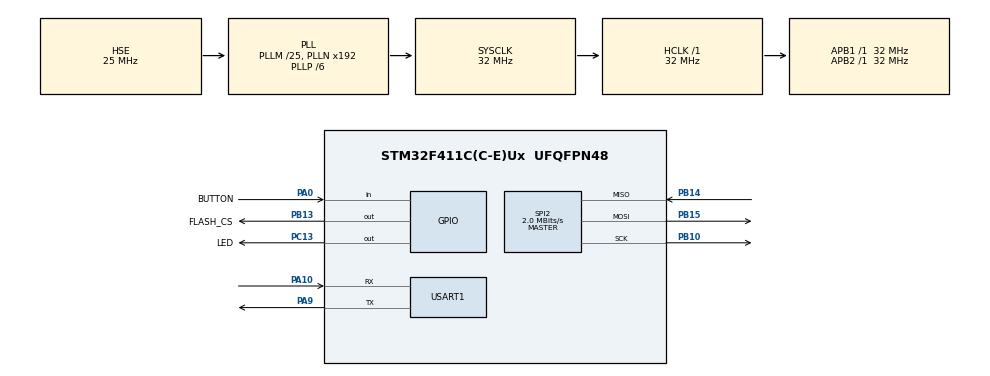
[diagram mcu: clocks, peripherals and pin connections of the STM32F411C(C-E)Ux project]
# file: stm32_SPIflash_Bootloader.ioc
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Mcu.Family=STM32F4
Mcu.Name=STM32F411C(C-E)Ux
Mcu.Package=UFQFPN48
NVIC.PriorityGroup=NVIC_PRIORITYGROUP_4
NVIC.USART1_IRQn=true\:0\:0\:false\:false\:true\:true\:true\:true
PA0-WKUP.GPIO_Label=BUTTON
PA0-WKUP.GPIO_PuPd=GPIO_PULLUP
PA0-WKUP.Signal=GPIO_Input
PA10.Mode=Asynchronous
PA10.Signal=USART1_RX
PA9.Mode=Asynchronous
PA9.Signal=USART1_TX
PB10.Mode=Full_Duplex_Master
PB10.Signal=SPI2_SCK
PB13.GPIO_Label=FLASH_CS
PB13.Signal=GPIO_Output
PB14.Mode=Full_Duplex_Master
PB14.Signal=SPI2_MISO
PB15.Mode=Full_Duplex_Master
PB15.Signal=SPI2_MOSI
PC13-ANTI_TAMP.GPIO_Label=LED
PC13-ANTI_TAMP.Signal=GPIO_Output
PH0\ -\ OSC_IN.Mode=HSE-External-Oscillator
PH0\ -\ OSC_IN.Signal=RCC_OSC_IN
PH1\ -\ OSC_OUT.Mode=HSE-External-Oscillator
PH1\ -\ OSC_OUT.Signal=RCC_OSC_OUT
ProjectManager.HeapSize=0x200
ProjectManager.StackSize=0x400
ProjectManager.TargetToolchain=STM32CubeIDE
RCC.48MHZClocksFreq_Value=48000000
RCC.AHBFreq_Value=32000000
RCC.APB1Freq_Value=32000000
RCC.APB1TimFreq_Value=32000000
RCC.APB2Freq_Value=32000000
RCC.APB2TimFreq_Value=32000000
RCC.CortexFreq_Value=32000000
RCC.HCLKFreq_Value=32000000
RCC.HSE_VALUE=25000000
RCC.HSI_VALUE=16000000
RCC.LSE_VALUE=32768
RCC.PLLM=25
RCC.PLLP=RCC_PLLP_DIV6
RCC.PLLSourceVirtual=RCC_PLLSOURCE_HSE
RCC.SYSCLKFreq_VALUE=32000000
RCC.SYSCLKSource=RCC_SYSCLKSOURCE_PLLCLK
RCC.VCOOutputFreq_Value=192000000
SPI2.BaudRatePrescaler=SPI_BAUDRATEPRESCALER_16
SPI2.CalculateBaudRate=2.0 MBits/s
SPI2.Direction=SPI_DIRECTION_2LINES
SPI2.Mode=SPI_MODE_MASTER
SPI2.VirtualType=VM_MASTER
USART1.VirtualMode=VM_ASYNC
board=custom

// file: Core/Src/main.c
/* USER CODE BEGIN Header */
/**
  ******************************************************************************
  * @file           : main.c
  * @brief          : Main program body
  ******************************************************************************
  * @attention
  *
  * Copyright (c) 2024 STMicroelectronics.
  * All rights reserved.
  *
  * This software is licensed under terms that can be found in the LICENSE file
  * in the root directory of this software component.
  * If no LICENSE file comes with this software, it is provided AS-IS.
  *
  ******************************************************************************
  */
/* USER CODE END Header */
#include "main.h"

/* USER CODE BEGIN Includes */
#include "stdio.h"
#include "boot.h"
#include "exflash.h"
/* USER CODE END Includes */

SPI_HandleTypeDef hspi2;

UART_HandleTypeDef huart1;
uint8_t rxdata[2];

void SystemClock_Config(void);
static void MX_GPIO_Init(void);
static void MX_USART1_UART_Init(void);
static void MX_SPI2_Init(void);
/* USER CODE BEGIN PFP */
extern void uart_int(uint8_t byte);
/* USER CODE END PFP */

/* USER CODE BEGIN 0 */
#define PUTCHAR_PROTOTYPE int __io_putchar(int ch)

PUTCHAR_PROTOTYPE
{
	//HAL_UART_Transmit(&huart1, &ch, 1, HAL_MAX_DELAY);
	//return ch;
}

uint8_t wbuff[16], rbuff[16];
void HAL_UART_RxCpltCallback(UART_HandleTypeDef *huart)
{
	if(huart == &huart1)
	{
		uart_int(rxdata[0]);
		HAL_UART_Receive_IT(&huart1, &rxdata[0], 1);
	}
}

/* USER CODE END 0 */

int main(void)
{

  /* MCU Configuration--------------------------------------------------------*/

  /* Reset of all peripherals, Initializes the Flash interface and the Systick. */
  HAL_Init();

  /* Configure the system clock */
  SystemClock_Config();

  /* Initialize all configured peripherals */
  MX_GPIO_Init();
  MX_USART1_UART_Init();
  MX_SPI2_Init();
  /* USER CODE BEGIN 2 */

  ef_readid();

  ef_GlobalBlockProtectionUnlock();
  HAL_UART_Receive_IT(&huart1, &rxdata[0], 1);

  ef_EraseSector(0x200000);

  for(int i=0;i <16;i++) wbuff[i] = i+20;

  ef_WriteBuffer(wbuff, 0x200000 , 16);

  HAL_Delay(100);

  ef_ReadBuffer(&rbuff[0], 0x200000 , 16);

  for(int i=0;i <16;i++)
  {
	  printf("%d ", rbuff[i]);
  }

  /* USER CODE END 2 */

  /* Infinite loop */
  /* USER CODE BEGIN WHILE */
  while (1)
  {

	if(is_new_packet())
	{
	  process_packet();  // Validate and process the packet
	}
    /* USER CODE END WHILE */

  }
}

void SystemClock_Config(void)
{
  RCC_OscInitTypeDef RCC_OscInitStruct = {0};
  RCC_ClkInitTypeDef RCC_ClkInitStruct = {0};

  /** Configure the main internal regulator output voltage
  */
  __HAL_RCC_PWR_CLK_ENABLE();
  __HAL_PWR_VOLTAGESCALING_CONFIG(PWR_REGULATOR_VOLTAGE_SCALE1);

  /** Initializes the RCC Oscillators according to the specified parameters
  * in the RCC_OscInitTypeDef structure.
  */
  RCC_OscInitStruct.OscillatorType = RCC_OSCILLATORTYPE_HSE;
  RCC_OscInitStruct.HSEState = RCC_HSE_ON;
  RCC_OscInitStruct.PLL.PLLState = RCC_PLL_ON;
  RCC_OscInitStruct.PLL.PLLSource = RCC_PLLSOURCE_HSE;
  RCC_OscInitStruct.PLL.PLLM = 25;
  RCC_OscInitStruct.PLL.PLLN = 192;
  RCC_OscInitStruct.PLL.PLLP = RCC_PLLP_DIV6;
  RCC_OscInitStruct.PLL.PLLQ = 4;
  if (HAL_RCC_OscConfig(&RCC_OscInitStruct) != HAL_OK)
  {
    Error_Handler();
  }

  /** Initializes the CPU, AHB and APB buses clocks
  */
  RCC_ClkInitStruct.ClockType = RCC_CLOCKTYPE_HCLK|RCC_CLOCKTYPE_SYSCLK
                              |RCC_CLOCKTYPE_PCLK1|RCC_CLOCKTYPE_PCLK2;
  RCC_ClkInitStruct.SYSCLKSource = RCC_SYSCLKSOURCE_PLLCLK;
  RCC_ClkInitStruct.AHBCLKDivider = RCC_SYSCLK_DIV1;
  RCC_ClkInitStruct.APB1CLKDivider = RCC_HCLK_DIV1;
  RCC_ClkInitStruct.APB2CLKDivider = RCC_HCLK_DIV1;

  if (HAL_RCC_ClockConfig(&RCC_ClkInitStruct, FLASH_LATENCY_1) != HAL_OK)
  {
    Error_Handler();
  }
}

static void MX_SPI2_Init(void)
{

  /* SPI2 parameter configuration*/
  hspi2.Instance = SPI2;
  hspi2.Init.Mode = SPI_MODE_MASTER;
  hspi2.Init.Direction = SPI_DIRECTION_2LINES;
  hspi2.Init.DataSize = SPI_DATASIZE_8BIT;
  hspi2.Init.CLKPolarity = SPI_POLARITY_LOW;
  hspi2.Init.CLKPhase = SPI_PHASE_1EDGE;
  hspi2.Init.NSS = SPI_NSS_SOFT;
  hspi2.Init.BaudRatePrescaler = SPI_BAUDRATEPRESCALER_32;
  hspi2.Init.FirstBit = SPI_FIRSTBIT_MSB;
  hspi2.Init.TIMode = SPI_TIMODE_DISABLE;
  hspi2.Init.CRCCalculation = SPI_CRCCALCULATION_DISABLE;
  hspi2.Init.CRCPolynomial = 10;
  if (HAL_SPI_Init(&hspi2) != HAL_OK)
  {
    Error_Handler();
  }

}

static void MX_USART1_UART_Init(void)
{

  huart1.Instance = USART1;
  huart1.Init.BaudRate = 115200;
  huart1.Init.WordLength = UART_WORDLENGTH_8B;
  huart1.Init.StopBits = UART_STOPBITS_1;
  huart1.Init.Parity = UART_PARITY_NONE;
  huart1.Init.Mode = UART_MODE_TX_RX;
  huart1.Init.HwFlowCtl = UART_HWCONTROL_NONE;
  huart1.Init.OverSampling = UART_OVERSAMPLING_16;
  if (HAL_UART_Init(&huart1) != HAL_OK)
  {
    Error_Handler();
  }

}

static void MX_GPIO_Init(void)
{
  GPIO_InitTypeDef GPIO_InitStruct = {0};

  /* GPIO Ports Clock Enable */
  __HAL_RCC_GPIOC_CLK_ENABLE();
  __HAL_RCC_GPIOH_CLK_ENABLE();
  __HAL_RCC_GPIOA_CLK_ENABLE();
  __HAL_RCC_GPIOB_CLK_ENABLE();

  /*Configure GPIO pin Output Level */
  HAL_GPIO_WritePin(LED_GPIO_Port, LED_Pin, GPIO_PIN_RESET);

  /*Configure GPIO pin Output Level */
  HAL_GPIO_WritePin(FLASH_CS_GPIO_Port, FLASH_CS_Pin, GPIO_PIN_RESET);

  /*Configure GPIO pin : LED_Pin */
  GPIO_InitStruct.Pin = LED_Pin;
  GPIO_InitStruct.Mode = GPIO_MODE_OUTPUT_PP;
  GPIO_InitStruct.Pull = GPIO_NOPULL;
  GPIO_InitStruct.Speed = GPIO_SPEED_FREQ_LOW;
  HAL_GPIO_Init(LED_GPIO_Port, &GPIO_InitStruct);

  /*Configure GPIO pin : BUTTON_Pin */
  GPIO_InitStruct.Pin = BUTTON_Pin;
  GPIO_InitStruct.Mode = GPIO_MODE_INPUT;
  GPIO_InitStruct.Pull = GPIO_PULLUP;
  HAL_GPIO_Init(BUTTON_GPIO_Port, &GPIO_InitStruct);

  /*Configure GPIO pin : FLASH_CS_Pin */
  GPIO_InitStruct.Pin = FLASH_CS_Pin;
  GPIO_InitStruct.Mode = GPIO_MODE_OUTPUT_PP;
  GPIO_InitStruct.Pull = GPIO_NOPULL;
  GPIO_InitStruct.Speed = GPIO_SPEED_FREQ_LOW;
  HAL_GPIO_Init(FLASH_CS_GPIO_Port, &GPIO_InitStruct);

  /*Configure GPIO pin : PB4 */
  GPIO_InitStruct.Pin = GPIO_PIN_4;
  GPIO_InitStruct.Mode = GPIO_MODE_AF_PP;
  GPIO_InitStruct.Pull = GPIO_NOPULL;
  GPIO_InitStruct.Speed = GPIO_SPEED_FREQ_VERY_HIGH;
  GPIO_InitStruct.Alternate = GPIO_AF5_SPI1;
  HAL_GPIO_Init(GPIOB, &GPIO_InitStruct);

}

void Error_Handler(void)
{
  __disable_irq();
  while (1)
  {
  }
}
